VERSION "Honda Accord B-CAN transmitter grouping"

NS_ :

BS_:

BU_: METER MICU XXX UNKNOWN

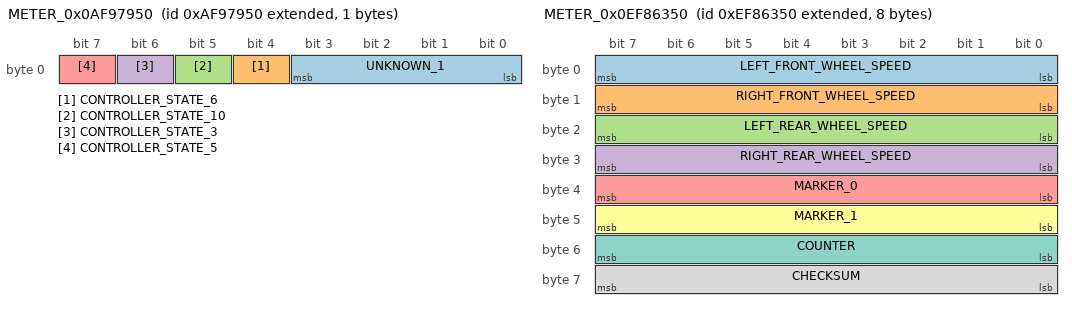
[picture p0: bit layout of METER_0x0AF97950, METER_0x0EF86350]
BO_ 2331605328 METER_0x0AF97950: 1 METER
 SG_ UNKNOWN_1 : 0|4@1+ (1,0) [0|15] ""  UNKNOWN
 SG_ CONTROLLER_STATE_6 : 4|1@1+ (1,0) [0|1] ""  UNKNOWN
 SG_ CONTROLLER_STATE_10 : 5|1@1+ (1,0) [0|1] ""  UNKNOWN
 SG_ CONTROLLER_STATE_3 : 6|1@1+ (1,0) [0|1] ""  UNKNOWN
 SG_ CONTROLLER_STATE_5 : 7|1@1+ (1,0) [0|1] ""  UNKNOWN

BO_ 2398643024 METER_0x0EF86350: 8 METER
 SG_ LEFT_FRONT_WHEEL_SPEED : 0|8@1+ (1,0) [0|255] "raw"  UNKNOWN
 SG_ RIGHT_FRONT_WHEEL_SPEED : 8|8@1+ (1,0) [0|255] "raw"  UNKNOWN
 SG_ LEFT_REAR_WHEEL_SPEED : 16|8@1+ (1,0) [0|255] "raw"  UNKNOWN
 SG_ RIGHT_REAR_WHEEL_SPEED : 24|8@1+ (1,0) [0|255] "raw"  UNKNOWN
 SG_ MARKER_0 : 32|8@1+ (1,0) [0|255] ""  UNKNOWN
 SG_ MARKER_1 : 40|8@1+ (1,0) [0|255] ""  UNKNOWN
 SG_ COUNTER : 48|8@1+ (1,0) [0|255] ""  UNKNOWN
 SG_ CHECKSUM : 56|8@1+ (1,0) [0|255] ""  UNKNOWN

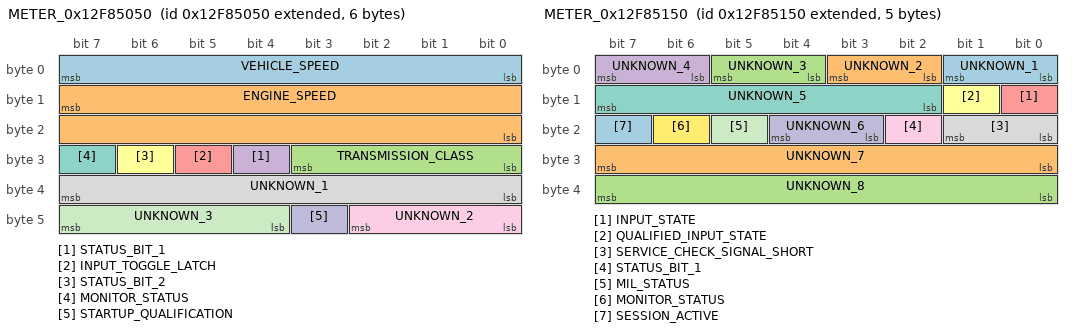
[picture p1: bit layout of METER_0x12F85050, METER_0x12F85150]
BO_ 2465747024 METER_0x12F85050: 6 METER
 SG_ VEHICLE_SPEED : 0|8@1+ (1,0) [0|255] "km/h"  UNKNOWN
 SG_ ENGINE_SPEED : 15|16@0+ (1,0) [0|65535] "rpm"  UNKNOWN
 SG_ TRANSMISSION_CLASS : 24|4@1+ (1,0) [0|15] ""  UNKNOWN
 SG_ STATUS_BIT_1 : 28|1@1+ (1,0) [0|1] ""  UNKNOWN
 SG_ INPUT_TOGGLE_LATCH : 29|1@1+ (1,0) [0|1] ""  UNKNOWN
 SG_ STATUS_BIT_2 : 30|1@1+ (1,0) [0|1] ""  UNKNOWN
 SG_ MONITOR_STATUS : 31|1@1+ (1,0) [0|1] ""  UNKNOWN
 SG_ UNKNOWN_1 : 32|8@1+ (1,0) [0|255] ""  UNKNOWN
 SG_ UNKNOWN_2 : 40|3@1+ (1,0) [0|7] ""  UNKNOWN
 SG_ STARTUP_QUALIFICATION : 43|1@1+ (1,0) [0|1] ""  UNKNOWN
 SG_ UNKNOWN_3 : 44|4@1+ (1,0) [0|15] ""  UNKNOWN

BO_ 2465747280 METER_0x12F85150: 5 METER
 SG_ UNKNOWN_1 : 0|2@1+ (1,0) [0|3] ""  UNKNOWN
 SG_ UNKNOWN_2 : 2|2@1+ (1,0) [0|3] ""  UNKNOWN
 SG_ UNKNOWN_3 : 4|2@1+ (1,0) [0|3] ""  UNKNOWN
 SG_ UNKNOWN_4 : 6|2@1+ (1,0) [0|3] ""  UNKNOWN
 SG_ INPUT_STATE : 8|1@1+ (1,0) [0|1] ""  UNKNOWN
 SG_ QUALIFIED_INPUT_STATE : 9|1@1+ (1,0) [0|1] ""  UNKNOWN
 SG_ UNKNOWN_5 : 10|6@1+ (1,0) [0|63] ""  UNKNOWN
 SG_ SERVICE_CHECK_SIGNAL_SHORT : 16|2@1+ (1,0) [0|3] ""  UNKNOWN
 SG_ STATUS_BIT_1 : 18|1@1+ (1,0) [0|1] ""  UNKNOWN
 SG_ UNKNOWN_6 : 19|2@1+ (1,0) [0|3] ""  UNKNOWN
 SG_ MIL_STATUS : 21|1@1+ (1,0) [0|1] ""  UNKNOWN
 SG_ MONITOR_STATUS : 22|1@1+ (1,0) [0|1] ""  UNKNOWN
 SG_ SESSION_ACTIVE : 23|1@1+ (1,0) [0|1] ""  UNKNOWN
 SG_ UNKNOWN_7 : 24|8@1+ (1,0) [0|255] ""  UNKNOWN
 SG_ UNKNOWN_8 : 32|8@1+ (1,0) [0|255] ""  UNKNOWN
VAL_ 2465747280 MIL_STATUS 0 "OFF" 1 "ON" ;

BO_ 2465747536 METER_0x12F85250: 4 METER
 SG_ ECT_SENSOR_1 : 0|8@1+ (1,-40) [-40|215] "degC"  UNKNOWN
 SG_ UNKNOWN_1 : 15|24@0+ (1,0) [0|16777215] ""  UNKNOWN

BO_ 2465748048 METER_0x12F85450: 8 METER
 SG_ SELECTED_PRESET : 0|5@1+ (1,0) [0|31] ""  UNKNOWN
 SG_ STATUS_BIT_1 : 5|1@1+ (1,0) [0|1] ""  UNKNOWN
 SG_ LIGHTING_SELECTION : 6|1@1+ (1,0) [0|1] ""  UNKNOWN
 SG_ LIGHTING_QUALIFIED : 7|1@1+ (1,0) [0|1] ""  UNKNOWN
 SG_ UNKNOWN_1 : 8|5@1+ (1,0) [0|31] ""  UNKNOWN
 SG_ PROCEDURE_CLASS : 13|2@1+ (1,0) [0|3] ""  UNKNOWN
 SG_ STATUS_BIT_2 : 15|1@1+ (1,0) [0|1] ""  UNKNOWN
 SG_ UNKNOWN_2 : 16|8@1+ (1,0) [0|255] ""  UNKNOWN
 SG_ UNKNOWN_3 : 24|8@1+ (1,0) [0|255] ""  UNKNOWN
 SG_ UNKNOWN_4 : 32|8@1+ (1,0) [0|255] ""  UNKNOWN
 SG_ MODE_PRESET : 40|5@1+ (1,0) [0|31] ""  UNKNOWN
 SG_ STATUS_BIT_3 : 45|1@1+ (1,0) [0|1] ""  UNKNOWN
 SG_ MODE_2 : 46|1@1+ (1,0) [0|1] ""  UNKNOWN
 SG_ MODE_2_PRESET_22 : 47|1@1+ (1,0) [0|1] ""  UNKNOWN
 SG_ UNKNOWN_5 : 48|4@1+ (1,0) [0|15] ""  UNKNOWN
 SG_ PROCEDURE : 52|4@1+ (1,0) [0|15] ""  UNKNOWN
 SG_ UNKNOWN_6 : 56|8@1+ (1,0) [0|255] ""  UNKNOWN

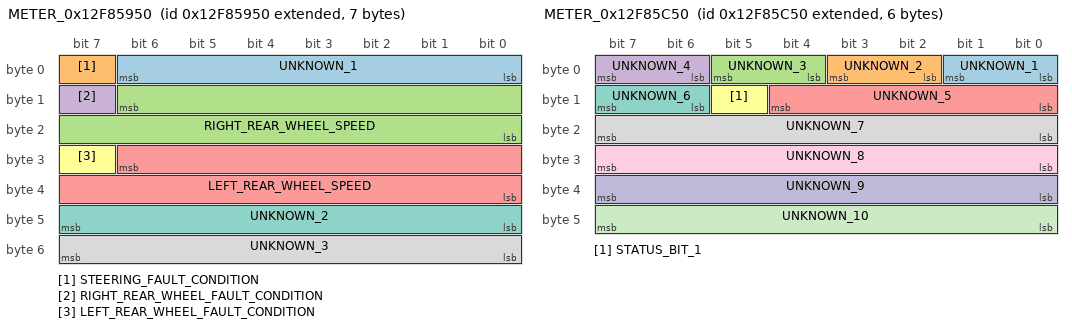
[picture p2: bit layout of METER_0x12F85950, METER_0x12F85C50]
BO_ 2465749328 METER_0x12F85950: 7 METER
 SG_ UNKNOWN_1 : 0|7@1+ (1,0) [0|127] ""  UNKNOWN
 SG_ STEERING_FAULT_CONDITION : 7|1@1+ (1,0) [0|1] ""  UNKNOWN
 SG_ RIGHT_REAR_WHEEL_SPEED : 14|15@0+ (1,0) [0|32767] "raw"  UNKNOWN
 SG_ RIGHT_REAR_WHEEL_FAULT_CONDITION : 15|1@1+ (1,0) [0|1] ""  UNKNOWN
 SG_ LEFT_REAR_WHEEL_SPEED : 30|15@0+ (1,0) [0|32767] "raw"  UNKNOWN
 SG_ LEFT_REAR_WHEEL_FAULT_CONDITION : 31|1@1+ (1,0) [0|1] ""  UNKNOWN
 SG_ UNKNOWN_2 : 40|8@1+ (1,0) [0|255] ""  UNKNOWN
 SG_ UNKNOWN_3 : 48|8@1+ (1,0) [0|255] ""  UNKNOWN

BO_ 2465750096 METER_0x12F85C50: 6 METER
 SG_ UNKNOWN_1 : 0|2@1+ (1,0) [0|3] ""  UNKNOWN
 SG_ UNKNOWN_2 : 2|2@1+ (1,0) [0|3] ""  UNKNOWN
 SG_ UNKNOWN_3 : 4|2@1+ (1,0) [0|3] ""  UNKNOWN
 SG_ UNKNOWN_4 : 6|2@1+ (1,0) [0|3] ""  UNKNOWN
 SG_ UNKNOWN_5 : 8|5@1+ (1,0) [0|31] ""  UNKNOWN
 SG_ STATUS_BIT_1 : 13|1@1+ (1,0) [0|1] ""  UNKNOWN
 SG_ UNKNOWN_6 : 14|2@1+ (1,0) [0|3] ""  UNKNOWN
 SG_ UNKNOWN_7 : 16|8@1+ (1,0) [0|255] ""  UNKNOWN
 SG_ UNKNOWN_8 : 24|8@1+ (1,0) [0|255] ""  UNKNOWN
 SG_ UNKNOWN_9 : 32|8@1+ (1,0) [0|255] ""  UNKNOWN
 SG_ UNKNOWN_10 : 40|8@1+ (1,0) [0|255] ""  UNKNOWN

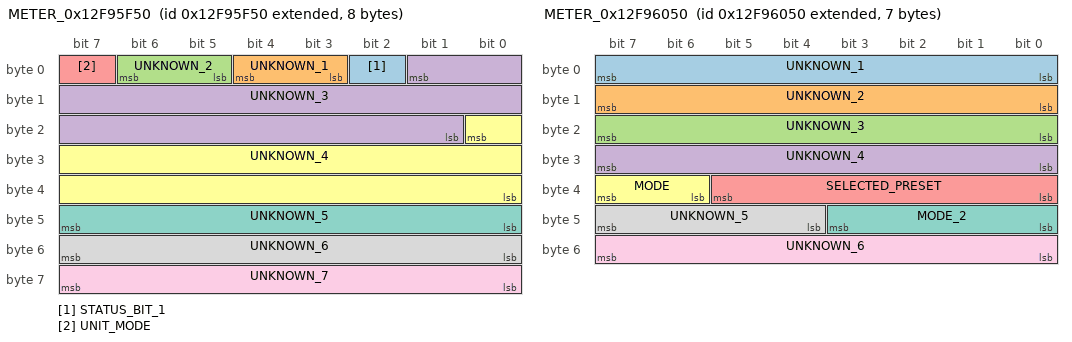
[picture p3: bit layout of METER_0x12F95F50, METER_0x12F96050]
BO_ 2465816400 METER_0x12F95F50: 8 METER
 SG_ STATUS_BIT_1 : 2|1@1+ (1,0) [0|1] ""  UNKNOWN
 SG_ UNKNOWN_1 : 3|2@1+ (1,0) [0|3] ""  UNKNOWN
 SG_ UNKNOWN_2 : 5|2@1+ (1,0) [0|3] ""  UNKNOWN
 SG_ UNKNOWN_3 : 1|17@0+ (1,0) [0|131071] ""  UNKNOWN
 SG_ UNIT_MODE : 7|1@1+ (1,0) [0|1] ""  UNKNOWN
 SG_ UNKNOWN_4 : 16|17@0+ (1,0) [0|131071] ""  UNKNOWN
 SG_ UNKNOWN_5 : 40|8@1+ (1,0) [0|255] ""  UNKNOWN
 SG_ UNKNOWN_6 : 48|8@1+ (1,0) [0|255] ""  UNKNOWN
 SG_ UNKNOWN_7 : 56|8@1+ (1,0) [0|255] ""  UNKNOWN

BO_ 2465816656 METER_0x12F96050: 7 METER
 SG_ UNKNOWN_1 : 0|8@1+ (1,0) [0|255] ""  UNKNOWN
 SG_ UNKNOWN_2 : 8|8@1+ (1,0) [0|255] ""  UNKNOWN
 SG_ UNKNOWN_3 : 16|8@1+ (1,0) [0|255] ""  UNKNOWN
 SG_ UNKNOWN_4 : 24|8@1+ (1,0) [0|255] ""  UNKNOWN
 SG_ SELECTED_PRESET : 32|6@1+ (1,0) [0|63] ""  UNKNOWN
 SG_ MODE : 38|2@1+ (1,0) [0|3] ""  UNKNOWN
 SG_ MODE_2 : 40|4@1+ (1,0) [0|15] ""  UNKNOWN
 SG_ UNKNOWN_5 : 44|4@1+ (1,0) [0|15] ""  UNKNOWN
 SG_ UNKNOWN_6 : 48|8@1+ (1,0) [0|255] ""  UNKNOWN

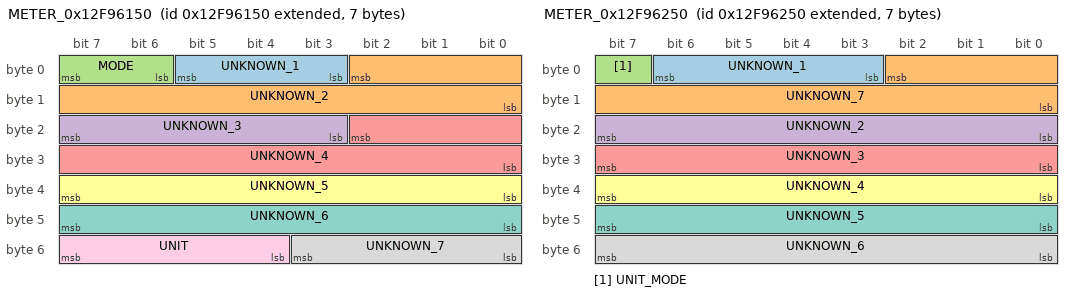
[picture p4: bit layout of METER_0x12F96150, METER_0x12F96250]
BO_ 2465816912 METER_0x12F96150: 7 METER
 SG_ UNKNOWN_1 : 3|3@1+ (1,0) [0|7] ""  UNKNOWN
 SG_ UNKNOWN_2 : 2|11@0+ (1,0) [0|2047] ""  UNKNOWN
 SG_ MODE : 6|2@1+ (1,0) [0|3] ""  UNKNOWN
 SG_ UNKNOWN_3 : 19|5@1+ (1,0) [0|31] ""  UNKNOWN
 SG_ UNKNOWN_4 : 18|11@0+ (1,0) [0|2047] ""  UNKNOWN
 SG_ UNKNOWN_5 : 32|8@1+ (1,0) [0|255] ""  UNKNOWN
 SG_ UNKNOWN_6 : 40|8@1+ (1,0) [0|255] ""  UNKNOWN
 SG_ UNKNOWN_7 : 48|4@1+ (1,0) [0|15] ""  UNKNOWN
 SG_ UNIT : 52|4@1+ (1,0) [0|15] ""  UNKNOWN

BO_ 2465817168 METER_0x12F96250: 7 METER
 SG_ UNKNOWN_1 : 3|4@1+ (1,0) [0|15] ""  UNKNOWN
 SG_ UNKNOWN_7 : 2|11@0+ (1,0) [0|2047] ""  UNKNOWN
 SG_ UNIT_MODE : 7|1@1+ (1,0) [0|1] ""  UNKNOWN
 SG_ UNKNOWN_2 : 16|8@1+ (1,0) [0|255] ""  UNKNOWN
 SG_ UNKNOWN_3 : 24|8@1+ (1,0) [0|255] ""  UNKNOWN
 SG_ UNKNOWN_4 : 32|8@1+ (1,0) [0|255] ""  UNKNOWN
 SG_ UNKNOWN_5 : 40|8@1+ (1,0) [0|255] ""  UNKNOWN
 SG_ UNKNOWN_6 : 48|8@1+ (1,0) [0|255] ""  UNKNOWN

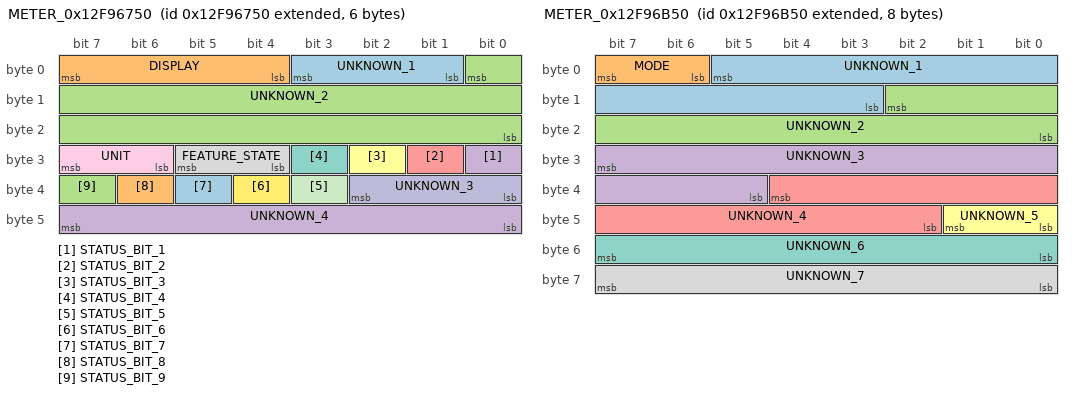
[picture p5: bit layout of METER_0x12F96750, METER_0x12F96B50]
BO_ 2465818448 METER_0x12F96750: 6 METER
 SG_ UNKNOWN_1 : 1|3@1+ (1,0) [0|7] ""  UNKNOWN
 SG_ DISPLAY : 4|4@1+ (1,0) [0|15] ""  UNKNOWN
 SG_ UNKNOWN_2 : 0|17@0+ (1,0) [0|131071] ""  UNKNOWN
 SG_ STATUS_BIT_1 : 24|1@1+ (1,0) [0|1] ""  UNKNOWN
 SG_ STATUS_BIT_2 : 25|1@1+ (1,0) [0|1] ""  UNKNOWN
 SG_ STATUS_BIT_3 : 26|1@1+ (1,0) [0|1] ""  UNKNOWN
 SG_ STATUS_BIT_4 : 27|1@1+ (1,0) [0|1] ""  UNKNOWN
 SG_ FEATURE_STATE : 28|2@1+ (1,0) [0|3] ""  UNKNOWN
 SG_ UNIT : 30|2@1+ (1,0) [0|3] ""  UNKNOWN
 SG_ UNKNOWN_3 : 32|3@1+ (1,0) [0|7] ""  UNKNOWN
 SG_ STATUS_BIT_5 : 35|1@1+ (1,0) [0|1] ""  UNKNOWN
 SG_ STATUS_BIT_6 : 36|1@1+ (1,0) [0|1] ""  UNKNOWN
 SG_ STATUS_BIT_7 : 37|1@1+ (1,0) [0|1] ""  UNKNOWN
 SG_ STATUS_BIT_8 : 38|1@1+ (1,0) [0|1] ""  UNKNOWN
 SG_ STATUS_BIT_9 : 39|1@1+ (1,0) [0|1] ""  UNKNOWN
 SG_ UNKNOWN_4 : 40|8@1+ (1,0) [0|255] ""  UNKNOWN

BO_ 2465819472 METER_0x12F96B50: 8 METER
 SG_ UNKNOWN_1 : 5|11@0+ (1,0) [0|2047] ""  UNKNOWN
 SG_ MODE : 6|2@1+ (1,0) [0|3] ""  UNKNOWN
 SG_ UNKNOWN_2 : 10|11@0+ (1,0) [0|2047] ""  UNKNOWN
 SG_ UNKNOWN_3 : 31|11@0+ (1,0) [0|2047] ""  UNKNOWN
 SG_ UNKNOWN_4 : 36|11@0+ (1,0) [0|2047] ""  UNKNOWN
 SG_ UNKNOWN_5 : 40|2@1+ (1,0) [0|3] ""  UNKNOWN
 SG_ UNKNOWN_6 : 48|8@1+ (1,0) [0|255] ""  UNKNOWN
 SG_ UNKNOWN_7 : 56|8@1+ (1,0) [0|255] ""  UNKNOWN

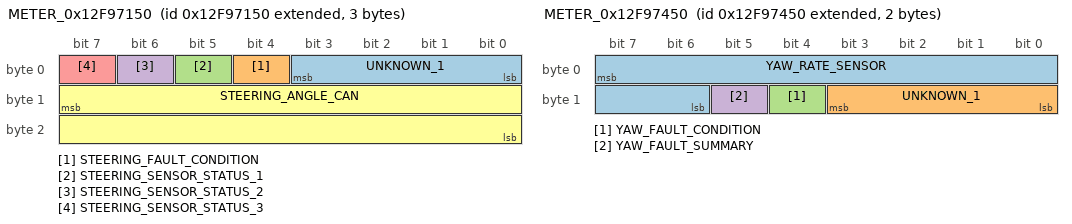
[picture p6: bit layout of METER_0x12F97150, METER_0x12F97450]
BO_ 2465821008 METER_0x12F97150: 3 METER
 SG_ UNKNOWN_1 : 0|4@1+ (1,0) [0|15] ""  UNKNOWN
 SG_ STEERING_FAULT_CONDITION : 4|1@1+ (1,0) [0|1] ""  UNKNOWN
 SG_ STEERING_SENSOR_STATUS_1 : 5|1@1+ (1,0) [0|1] ""  UNKNOWN
 SG_ STEERING_SENSOR_STATUS_2 : 6|1@1+ (1,0) [0|1] ""  UNKNOWN
 SG_ STEERING_SENSOR_STATUS_3 : 7|1@1+ (1,0) [0|1] ""  UNKNOWN
 SG_ STEERING_ANGLE_CAN : 15|16@0+ (1,0) [0|65535] "raw"  UNKNOWN

BO_ 2465821520 METER_0x12F97350: 2 METER
 SG_ UNKNOWN_1 : 0|8@1+ (1,0) [0|255] ""  UNKNOWN
 SG_ UNKNOWN_2 : 8|8@1+ (1,0) [0|255] ""  UNKNOWN

BO_ 2465821776 METER_0x12F97450: 2 METER
 SG_ YAW_RATE_SENSOR : 7|10@0+ (1,0) [0|1023] "raw"  UNKNOWN
 SG_ UNKNOWN_1 : 8|4@1+ (1,0) [0|15] ""  UNKNOWN
 SG_ YAW_FAULT_CONDITION : 12|1@1+ (1,0) [0|1] ""  UNKNOWN
 SG_ YAW_FAULT_SUMMARY : 13|1@1+ (1,0) [0|1] ""  UNKNOWN

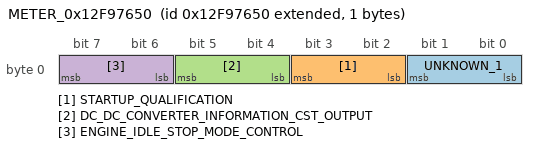
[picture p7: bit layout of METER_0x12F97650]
BO_ 2465822288 METER_0x12F97650: 1 METER
 SG_ UNKNOWN_1 : 0|2@1+ (1,0) [0|3] ""  UNKNOWN
 SG_ STARTUP_QUALIFICATION : 2|2@1+ (1,0) [0|3] ""  UNKNOWN
 SG_ DC_DC_CONVERTER_INFORMATION_CST_OUTPUT : 4|2@1+ (1,0) [0|3] ""  UNKNOWN
 SG_ ENGINE_IDLE_STOP_MODE_CONTROL : 6|2@1+ (1,0) [0|3] ""  UNKNOWN

BO_ 2465822800 METER_0x12F97850: 1 METER
 SG_ UNKNOWN_1 : 0|5@1+ (1,0) [0|31] ""  UNKNOWN
 SG_ SERIAL_STATUS : 5|3@1+ (1,0) [0|7] ""  UNKNOWN

BO_ 2532860496 METER_0x16F86250: 8 METER
 SG_ PAGE M : 0|4@1+ (1,0) [0|15] ""  UNKNOWN
 SG_ MULTIPLEX_GROUP : 4|2@1+ (1,0) [0|3] ""  UNKNOWN
 SG_ HEADER : 6|2@1+ (1,0) [0|3] ""  UNKNOWN
 SG_ RSVD_1 m0 : 8|8@1+ (1,0) [0|255] ""  UNKNOWN
 SG_ P01_VIN_1_6_BYTE_0 m1 : 8|8@1+ (1,0) [0|255] ""  UNKNOWN
 SG_ P02_VIN_7_12_BYTE_0 m2 : 8|8@1+ (1,0) [0|255] ""  UNKNOWN
 SG_ P03_VIN_13_17_BYTE_0 m3 : 8|8@1+ (1,0) [0|255] ""  UNKNOWN
 SG_ P04_ECUID1 m4 : 8|8@1+ (1,0) [0|255] ""  UNKNOWN
 SG_ P06_IAT_SENSOR_1_V m6 : 8|8@1+ (0.019600000232458115,0) [0.0|4.998000059276819] "V"  UNKNOWN
 SG_ P07_VEHICLE_SPEED_PCM m7 : 8|8@1+ (1,0) [0|255] "km/h"  UNKNOWN
 SG_ RSVD_2 m10 : 8|8@1+ (1,0) [0|255] ""  UNKNOWN
 SG_ P0B_FSS m11 : 8|8@1+ (1,0) [0|255] ""  UNKNOWN
 SG_ RSVD_3 m12 : 8|8@1+ (1,0) [0|255] ""  UNKNOWN
 SG_ RSVD_4 m13 : 8|8@1+ (1,0) [0|255] ""  UNKNOWN
 SG_ P0F_FUEL_LEVEL m15 : 8|8@1+ (0.39215686274509803,0) [0.0|100.0] "%"  UNKNOWN
 SG_ P05_ENGINE_SPEED m5 : 15|16@0+ (0.25,0) [0.0|16383.75] "rpm"  UNKNOWN
 SG_ P08_APP_SENSOR m8 : 15|16@0+ (0.005,0) [0.0|327.675] "%"  UNKNOWN
 SG_ P09_TARGET_TH_VLV m9 : 15|16@0+ (0.005,0) [0.0|327.675] "deg"  UNKNOWN
 SG_ P0E_MAF_SENSOR m14 : 15|16@0+ (0.01,0) [0.0|655.35] "g/s"  UNKNOWN
 SG_ P01_VIN_1_6_BYTE_1 m1 : 16|8@1+ (1,0) [0|255] ""  UNKNOWN
 SG_ P02_VIN_7_12_BYTE_1 m2 : 16|8@1+ (1,0) [0|255] ""  UNKNOWN
 SG_ P03_VIN_13_17_BYTE_1 m3 : 16|8@1+ (1,0) [0|255] ""  UNKNOWN
 SG_ P04_ECUID2 m4 : 16|8@1+ (1,0) [0|255] ""  UNKNOWN
 SG_ P06_IAT_SENSOR_1_DEG_C m6 : 16|8@1+ (1,-40) [-40|215] "degC"  UNKNOWN
 SG_ P07_CLV m7 : 16|8@1+ (0.39215686274509803,0) [0.0|100.0] "%"  UNKNOWN
 SG_ RSVD_5 m10 : 16|8@1+ (1,0) [0|255] ""  UNKNOWN
 SG_ P0B_HO2S_S2 m11 : 16|8@1+ (0.019600000232458115,0) [0.0|4.998000059276819] "V"  UNKNOWN
 SG_ RSVD_6 m12 : 16|8@1+ (1,0) [0|255] ""  UNKNOWN
 SG_ RSVD_7 m15 : 16|8@1+ (1,0) [0|255] ""  UNKNOWN
 SG_ P00_DIAGNOSTIC_EVENT_OR_FREEZE_DTC m0 : 23|16@0+ (1,0) [0|65535] ""  UNKNOWN
 SG_ P0D_AF_SENSOR m13 : 23|16@0+ (1,0) [0|65535] ""  UNKNOWN
 SG_ P01_VIN_1_6_BYTE_2 m1 : 24|8@1+ (1,0) [0|255] ""  UNKNOWN
 SG_ P02_VIN_7_12_BYTE_2 m2 : 24|8@1+ (1,0) [0|255] ""  UNKNOWN
 SG_ P03_VIN_13_17_BYTE_2 m3 : 24|8@1+ (1,0) [0|255] ""  UNKNOWN
 SG_ P04_ECUID3 m4 : 24|8@1+ (1,0) [0|255] ""  UNKNOWN
 SG_ P05_TP_SENSOR m5 : 24|8@1+ (0.39215686274509803,0) [0.0|100.0] "%"  UNKNOWN
 SG_ P06_MAP_SENSOR_V m6 : 24|8@1+ (0.019600000232458115,0) [0.0|4.998000059276819] "V"  UNKNOWN
 SG_ P07_SPARK_ADVANCE m7 : 24|8@1+ (0.5,-64) [-64.0|63.5] "deg"  UNKNOWN
 SG_ P08_TP_SENSOR_A m8 : 24|8@1+ (0.019600000232458115,0) [0.0|4.998000059276819] "V"  UNKNOWN
 SG_ P09_THROTTLE_BASELINE_1_TBD m9 : 24|8@1+ (1,0) [0|255] ""  UNKNOWN
 SG_ RSVD_8 m11 : 24|8@1+ (1,0) [0|255] ""  UNKNOWN
 SG_ RSVD_9 m12 : 24|8@1+ (1,0) [0|255] ""  UNKNOWN
 SG_ P0E_CMP_CTRL m14 : 24|8@1+ (0.5,-20) [-20.0|107.5] "deg"  UNKNOWN
 SG_ RSVD_10 m15 : 24|8@1+ (1,0) [0|255] ""  UNKNOWN
 SG_ P0A_AF_LAMBDA m10 : 31|16@0+ (3.0517578125e-05,0) [0.0|1.999969482421875] "ratio"  UNKNOWN
 SG_ P00_FORMAT_OR_LENGTH m0 : 32|8@1+ (1,0) [0|255] ""  UNKNOWN
 SG_ P01_VIN_1_6_BYTE_3 m1 : 32|8@1+ (1,0) [0|255] ""  UNKNOWN
 SG_ P02_VIN_7_12_BYTE_3 m2 : 32|8@1+ (1,0) [0|255] ""  UNKNOWN
 SG_ P03_VIN_13_17_BYTE_3 m3 : 32|8@1+ (1,0) [0|255] ""  UNKNOWN
 SG_ P04_ECUID4 m4 : 32|8@1+ (1,0) [0|255] ""  UNKNOWN
 SG_ P05_REL_TP_SENSOR m5 : 32|8@1+ (0.39215686274509803,0) [0.0|100.0] "%"  UNKNOWN
 SG_ P06_MAP_SENSOR_KPA m6 : 32|8@1+ (1,0) [0|255] "kPa"  UNKNOWN
 SG_ P07_CONTROL_MODULE_VOLTAGE_CLAMPED m7 : 32|8@1+ (1,0) [0|255] ""  UNKNOWN
 SG_ P08_TP_SENSOR_B m8 : 32|8@1+ (0.019600000232458115,0) [0.0|4.998000059276819] "V"  UNKNOWN
 SG_ P09_THROTTLE_BASELINE_2_TBD m9 : 32|8@1+ (1,0) [0|255] ""  UNKNOWN
 SG_ RSVD_11 m11 : 32|8@1+ (1,0) [0|255] ""  UNKNOWN
 SG_ RSVD_12 m12 : 32|8@1+ (1,0) [0|255] ""  UNKNOWN
 SG_ P0D_MAF_SENSOR m13 : 32|8@1+ (0.019600000232458115,0) [0.0|4.998000059276819] "V"  UNKNOWN
 SG_ RSVD_13 m15 : 32|8@1+ (1,0) [0|255] ""  UNKNOWN
 SG_ P0E_ENGINE_RUNTIME m14 : 39|16@0+ (1,0) [0|65535] "s"  UNKNOWN
 SG_ RSVD_14 m0 : 40|8@1+ (1,0) [0|255] ""  UNKNOWN
 SG_ P01_VIN_1_6_BYTE_4 m1 : 40|8@1+ (1,0) [0|255] ""  UNKNOWN
 SG_ P02_VIN_7_12_BYTE_4 m2 : 40|8@1+ (1,0) [0|255] ""  UNKNOWN
 SG_ P03_VIN_13_17_BYTE_4 m3 : 40|8@1+ (1,0) [0|255] ""  UNKNOWN
 SG_ P04_ECUID5 m4 : 40|8@1+ (1,0) [0|255] ""  UNKNOWN
 SG_ P05_ECT_SENSOR_1_V m5 : 40|8@1+ (0.019600000232458115,0) [0.0|4.998000059276819] "V"  UNKNOWN
 SG_ P06_BARO_SENSOR_V m6 : 40|8@1+ (0.019600000232458115,0) [0.0|4.998000059276819] "V"  UNKNOWN
 SG_ P07_APP_SENSOR_A m7 : 40|8@1+ (0.019600000232458115,0) [0.0|4.998000059276819] "V"  UNKNOWN
 SG_ P0A_AF_FB_ST_FUEL_TRIM m10 : 40|8@1+ (0.0078125,0) [0.0|1.9921875] "ratio"  UNKNOWN
 SG_ RSVD_15 m11 : 40|8@1+ (1,0) [0|255] ""  UNKNOWN
 SG_ RSVD_16 m15 : 40|8@1+ (1,0) [0|255] ""  UNKNOWN
 SG_ P08_THROTTLE_VLV m8 : 47|16@0+ (0.005,0) [0.0|327.675] "deg"  UNKNOWN
 SG_ P09_IDLE_TARGET_TH m9 : 47|16@0+ (0.005,0) [0.0|327.675] "deg"  UNKNOWN
 SG_ P0C_F_INJECTOR m12 : 47|16@0+ (0.004,0) [0.0|262.14] "ms"  UNKNOWN
 SG_ P0D_AF_LAMBDA_CMD m13 : 47|16@0+ (3.0517578125e-05,0) [0.0|1.999969482421875] "ratio"  UNKNOWN
 SG_ RSVD_17 m0 : 48|8@1+ (1,0) [0|255] ""  UNKNOWN
 SG_ P01_VIN_1_6_BYTE_5 m1 : 48|8@1+ (1,0) [0|255] ""  UNKNOWN
 SG_ P02_VIN_7_12_BYTE_5 m2 : 48|8@1+ (1,0) [0|255] ""  UNKNOWN
 SG_ P03_IDENTIFICATION_EXTRA_BYTE_TBD m3 : 48|8@1+ (1,0) [0|255] ""  UNKNOWN
 SG_ RSVD_18 m4 : 48|8@1+ (1,0) [0|255] ""  UNKNOWN
 SG_ P05_ECT_SENSOR_1_DEG_C m5 : 48|8@1+ (1,-40) [-40|215] "degC"  UNKNOWN
 SG_ P06_BARO_SENSOR_KPA m6 : 48|8@1+ (1,0) [0|255] "kPa"  UNKNOWN
 SG_ P07_APP_SENSOR_B m7 : 48|8@1+ (0.019600000232458115,0) [0.0|4.998000059276819] "V"  UNKNOWN
 SG_ P0A_AF_FB_AVE_LT_FUEL_TRIM m10 : 48|8@1+ (0.0078125,0) [0.0|1.9921875] "ratio"  UNKNOWN
 SG_ RSVD_19 m11 : 48|8@1+ (1,0) [0|255] ""  UNKNOWN
 SG_ P0E_EVAP_PC_DUTY m14 : 48|8@1+ (0.39215686274509803,0) [0.0|100.0] "%"  UNKNOWN
 SG_ RSVD_20 m15 : 48|8@1+ (1,0) [0|255] ""  UNKNOWN
 SG_ CHECKSUM : 56|4@1+ (1,0) [0|15] ""  UNKNOWN
 SG_ COUNTER : 60|2@1+ (1,0) [0|3] ""  UNKNOWN
 SG_ UNKNOWN_7 : 62|2@1+ (1,0) [0|3] ""  UNKNOWN
CM_ SG_ 2532860496 P04_ECUID1 "CANFI: ECUID1";
CM_ SG_ 2532860496 P06_IAT_SENSOR_1_V "CANFI: IAT Sensor (1)";
CM_ SG_ 2532860496 P07_VEHICLE_SPEED_PCM "CANFI: Vehicle Speed(PCM)";
CM_ SG_ 2532860496 P0B_FSS "CANFI: FSS";
VAL_ 2532860496 P0B_FSS 0 "NONE" 1 "OL COND" 2 "CLOSED" 4 "OL DRV" 8 "OL DTC" 16 "CL O2SX" ;
CM_ SG_ 2532860496 P0F_FUEL_LEVEL "CANFI: Fuel Level";
CM_ SG_ 2532860496 P05_ENGINE_SPEED "CANFI: Engine Speed";
CM_ SG_ 2532860496 P08_APP_SENSOR "CANFI: APP Sensor";
CM_ SG_ 2532860496 P09_TARGET_TH_VLV "CANFI: Target TH VLV";
CM_ SG_ 2532860496 P0E_MAF_SENSOR "CANFI: MAF Sensor";
CM_ SG_ 2532860496 P04_ECUID2 "CANFI: ECUID2";
CM_ SG_ 2532860496 P06_IAT_SENSOR_1_DEG_C "CANFI: IAT Sensor (1)";
CM_ SG_ 2532860496 P07_CLV "CANFI: CLV";
CM_ SG_ 2532860496 P0B_HO2S_S2 "CANFI: HO2S S2";
CM_ SG_ 2532860496 P0D_AF_SENSOR "CANFI: AF Sensor";
CM_ SG_ 2532860496 P04_ECUID3 "CANFI: ECUID3";
CM_ SG_ 2532860496 P05_TP_SENSOR "CANFI: TP Sensor";
CM_ SG_ 2532860496 P06_MAP_SENSOR_V "CANFI: MAP Sensor";
CM_ SG_ 2532860496 P07_SPARK_ADVANCE "CANFI: Spark Advance";
CM_ SG_ 2532860496 P08_TP_SENSOR_A "CANFI: TP Sensor A";
CM_ SG_ 2532860496 P0E_CMP_CTRL "CANFI: CMP Ctrl";
CM_ SG_ 2532860496 P0A_AF_LAMBDA "CANFI: AF Lambda";
CM_ SG_ 2532860496 P04_ECUID4 "CANFI: ECUID4";
CM_ SG_ 2532860496 P05_REL_TP_SENSOR "CANFI: REL TP Sensor";
CM_ SG_ 2532860496 P06_MAP_SENSOR_KPA "CANFI: MAP Sensor";
CM_ SG_ 2532860496 P08_TP_SENSOR_B "CANFI: TP Sensor B";
CM_ SG_ 2532860496 P0D_MAF_SENSOR "CANFI: MAF Sensor";
CM_ SG_ 2532860496 P04_ECUID5 "CANFI: ECUID5";
CM_ SG_ 2532860496 P05_ECT_SENSOR_1_V "CANFI: ECT Sensor 1";
CM_ SG_ 2532860496 P06_BARO_SENSOR_V "CANFI: Baro Sensor";
CM_ SG_ 2532860496 P07_APP_SENSOR_A "CANFI: APP Sensor A";
CM_ SG_ 2532860496 P0A_AF_FB_ST_FUEL_TRIM "CANFI: AF FB (ST Fuel Trim)";
CM_ SG_ 2532860496 P08_THROTTLE_VLV "CANFI: Throttle VLV";
CM_ SG_ 2532860496 P09_IDLE_TARGET_TH "CANFI: Idle Target TH";
CM_ SG_ 2532860496 P0C_F_INJECTOR "CANFI: F Injector";
CM_ SG_ 2532860496 P0D_AF_LAMBDA_CMD "CANFI: AF Lambda Cmd";
CM_ SG_ 2532860496 P05_ECT_SENSOR_1_DEG_C "CANFI: ECT Sensor 1";
CM_ SG_ 2532860496 P06_BARO_SENSOR_KPA "CANFI: Baro Sensor";
CM_ SG_ 2532860496 P07_APP_SENSOR_B "CANFI: APP Sensor B";
CM_ SG_ 2532860496 P0A_AF_FB_AVE_LT_FUEL_TRIM "CANFI: AF FB AVE (LT Fuel Trim)";
CM_ SG_ 2532860496 P0E_EVAP_PC_DUTY "CANFI: EVAP PC Duty";
CM_ BO_ 2532860496 "K24 CVT diagnostic snapshot reference. Values may be stored rather than live; other powertrains may differ.";
